# USB0_CTRL register map
Vendor: Texas Instruments
Peripheral module from a debugger description file (folder am335x).
Registers are 32-bit, read-write, no defined reset value unless marked. A register's access mark holds for its fields unless they carry their own. Offsets are as the file gives them; lines under a group give offsets from that group; [hi:lo] are bit positions; {n}, {i} and the like mark numbered series; 'fields as' and 'values as' point back to an identical list; <NAME> marks a mode.

## USB0_CTRL
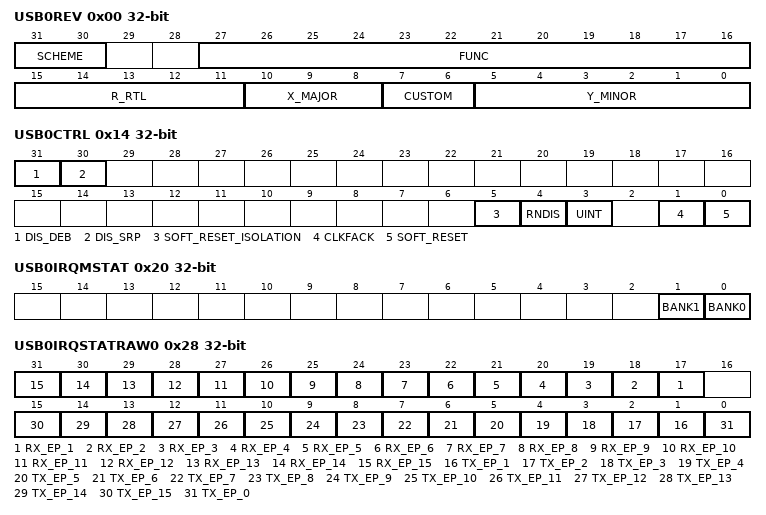
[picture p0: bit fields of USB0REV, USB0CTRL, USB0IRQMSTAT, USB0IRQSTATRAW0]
0x00 USB0REV ro
  [31:30] SCHEME — Used to distinguish between legacy interface scheme and current. 0 = Legacy 1 = Current
  [27:16] FUNC — Function indicates a software compatible module family.
  [15:11] R_RTL — RTL revision. Will vary depending on release.
  [10:8] X_MAJOR — Major revision.
  [7:6] CUSTOM — Custom revision
  [5:0] Y_MINOR — Minor revision. USB0 Revision Register
0x14 USB0CTRL
  [31] DIS_DEB — Disable the VBUS debouncer circuit fix
  [30] DIS_SRP — Disable the OTG Session Request Protocol (SRP) AVALID circuit fix. When enabled (=0) this allows additional time for the VBUS signal to be measured against the VBUS thresholds. The time is specified in the USB0 SRP Fix Time Register.
  [5] SOFT_RESET_ISOLATION — Soft reset isolation. When high this bit forces all USB0 signals that connect to the USBSS to known values during a soft reset via bit 0 of this register. This bit should be set high prior to setting bit 0 and cleared after bit 0 is cleared.
  [4] RNDIS — Global RNDIS mode enable for all endpoints.
  [3] UINT — USB interrupt enable 1 = Legacy 0 = Current (recommended setting); If uint is set high, then the mentor controller generic interrupt for USB[9] will be generated (if enabled). This requires S/W to read the mentor controller's registers to determine which interrupt from USB[0] to USB[7] that occurred.; If uint is set low, then the usb20otg_f module will automatically read the mentor controller's registers and set the appropriate interrupt from USB[0] to USB[7] (if enabled). The generic interrupt for USB[9] will not be generated.
  [1] CLKFACK — Clock stop fast ack enable.
  [0] SOFT_RESET — Software reset of USB0. Write 0 = no action Write 1 = Initiate software reset Read 0 = Reset done, no action Read 1 = Reset ongoing; Both the soft_reset and soft_reset_isolation bits should be asserted simultaneously. This will cause the following sequence of actions to occur over multiple cycles:;; - All USB0 output signals will go to a known constant value via multiplexers. This removes the possibility of timing errors due to the asynchronous resets.; - All USB0 registers will be reset.; - The USB0 resets will be de-asserted.; - The reset isolation multiplexer inputs will be de-selected.; - Both the soft_reset and soft_reset_isolation bits will be automatically cleared.;; Setting only the soft_reset_isolation bit will cause all USB0 output signals to go to a known constant value via multiplexers. This will prevent future access to USB0. To clear this condition the USBSS must be reset via a hard or soft reset.
0x18 USB0STAT ro
  [0] DRVVBUS — Current DRVVBUS value USB0 Status Register
0x20 USB0IRQMSTAT ro
  [1] BANK1 — 0: No events pending from IRQ_STATUS_1 1: At least one event is pending from IRQ_STATUS_1
  [0] BANK0 — 0: No events pending from IRQ_STATUS_0 1: At least one event is pending from IRQ_STATUS_0 USB0 IRQ_MERGED_STATUS Register
0x28 USB0IRQSTATRAW0
  [n+16] RX_EP_{n} (n=1..15) — Interrupt status for RX endpoint {n}
  [n] TX_EP_{n} (n=1..15) — Interrupt status for TX endpoint {n}
  [0] TX_EP_0 — Interrupt status for TX endpoint 0 USB0 IRQ_STATUS_RAW_0 Register
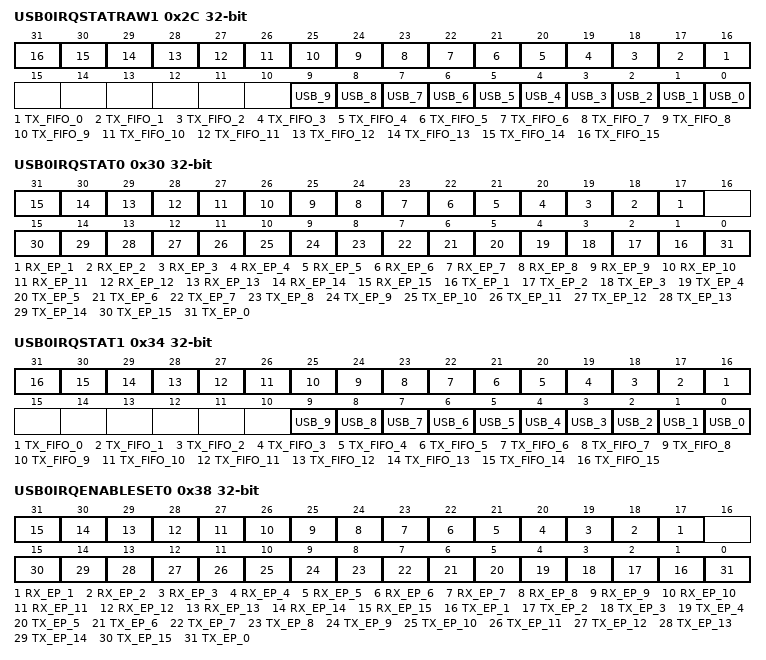
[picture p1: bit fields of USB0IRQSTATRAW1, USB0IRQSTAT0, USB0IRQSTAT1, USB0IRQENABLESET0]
0x2C USB0IRQSTATRAW1
  [n+16] TX_FIFO_{n} (n=0..15) — Interrupt status for TX FIFO endpoint {n}
  [9] USB_9 — Interrupt status for Mentor controller USB_INT generic interrupt
  [8] USB_8 — Interrupt status for DRVVBUS level change
  [7] USB_7 — Interrupt status for VBUS < VBUS valid threshold
  [6] USB_6 — Interrupt status for SRP detected
  [5] USB_5 — Interrupt status for device disconnected (host mode)
  [4] USB_4 — Interrupt status for device connected (host mode)
  [3] USB_3 — Interrupt status for SOF started
  [2] USB_2 — Interrupt status for Reset signaling detected (peripheral mode) Babble detected (host mode)
  [1] USB_1 — Interrupt status for Resume signaling detected
  [0] USB_0 — Interrupt status for Suspend signaling detected USB0 IRQ_STATUS_RAW_1 Register
0x30 USB0IRQSTAT0
  [n+16] RX_EP_{n} (n=1..15) — Interrupt status for RX endpoint {n}
  [n] TX_EP_{n} (n=1..15) — Interrupt status for TX endpoint {n}
  [0] TX_EP_0 — Interrupt status for TX endpoint 0 USB0 IRQ_STATUS_0 Register
0x34 USB0IRQSTAT1
  [n+16] TX_FIFO_{n} (n=0..15) — Interrupt status for TX FIFO endpoint {n}
  [9] USB_9 — Interrupt status for Mentor controller USB_INT generic interrupt
  [8] USB_8 — Interrupt status for DRVVBUS level change
  [7] USB_7 — Interrupt status for VBUS < VBUS valid threshold
  [6] USB_6 — Interrupt status for SRP detected
  [5] USB_5 — Interrupt status for device disconnected (host mode)
  [4] USB_4 — Interrupt status for device connected (host mode)
  [3] USB_3 — Interrupt status for SOF started
  [2] USB_2 — Interrupt status for Reset signaling detected (peripheral mode) Babble detected (host mode)
  [1] USB_1 — Interrupt status for Resume signaling detected
  [0] USB_0 — Interrupt status for Suspend signaling detected USB0 IRQ_STATUS_1 Register
0x38 USB0IRQENABLESET0
  [n+16] RX_EP_{n} (n=1..15) — Interrupt enable for RX endpoint {n}
  [n] TX_EP_{n} (n=1..15) — Interrupt enable for TX endpoint {n}
  [0] TX_EP_0 — Interrupt enable for TX endpoint 0 USB0 IRQ_ENABLE_SET_0 Register
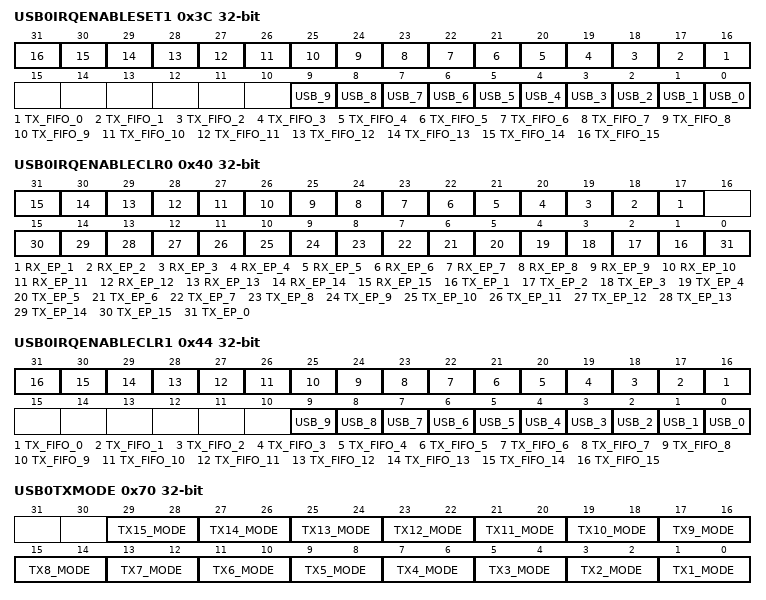
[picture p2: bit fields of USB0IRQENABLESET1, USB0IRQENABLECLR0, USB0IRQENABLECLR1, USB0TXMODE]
0x3C USB0IRQENABLESET1
  [n+16] TX_FIFO_{n} (n=0..15) — Interrupt enable for TX FIFO endpoint {n}
  [9] USB_9 — Interrupt enable for Mentor controller USB_INT generic interrupt
  [8] USB_8 — Interrupt enable for DRVVBUS level change
  [7] USB_7 — Interrupt enable for VBUS < VBUS valid threshold
  [6] USB_6 — Interrupt enable for SRP detected
  [5] USB_5 — Interrupt enable for device disconnected (host mode)
  [4] USB_4 — Interrupt enable for device connected (host mode)
  [3] USB_3 — Interrupt enable for SOF started
  [2] USB_2 — Interrupt enable for Reset signaling detected (peripheral mode) Babble detected (host mode)
  [1] USB_1 — Interrupt enable for Resume signaling detected
  [0] USB_0 — Interrupt enable for Suspend signaling detected USB0 IRQ_ENABLE_SET_1 Register
0x40 USB0IRQENABLECLR0
  [n+16] RX_EP_{n} (n=1..15) — Interrupt enable for RX endpoint {n}
  [n] TX_EP_{n} (n=1..15) — Interrupt enable for TX endpoint {n}
  [0] TX_EP_0 — Interrupt enable for TX endpoint 0 USB0 IRQ_ENABLE_CLR_0 Register
0x44 USB0IRQENABLECLR1
  [n+16] TX_FIFO_{n} (n=0..15) — Interrupt enable for TX FIFO endpoint {n}
  [9] USB_9 — Interrupt enable for Mentor controller USB_INT generic interrupt
  [8] USB_8 — Interrupt enable for DRVVBUS level change
  [7] USB_7 — Interrupt enable for VBUS < VBUS valid threshold
  [6] USB_6 — Interrupt enable for SRP detected
  [5] USB_5 — Interrupt enable for device disconnected (host mode)
  [4] USB_4 — Interrupt enable for device connected (host mode)
  [3] USB_3 — Interrupt enable for SOF started
  [2] USB_2 — Interrupt enable for Reset signaling detected (peripheral mode) Babble detected (host mode)
  [1] USB_1 — Interrupt enable for Resume signaling detected
  [0] USB_0 — Interrupt enable for Suspend signaling detected USB0 IRQ_ENABLE_CLR_1 Register
0x70 USB0TXMODE
  [2n-1:2n-2] TX{n}_MODE (n=2..15) — 00: Transparent Mode on TX endpoint {n-1} 01: RNDIS Mode on TX endpoint {n-1} 10: CDC Mode on TX endpoint {n-1} 11: Generic RNDIS Mode on TX endpoint {n-1}
  [1:0] TX1_MODE — 00: Transparent Mode on TX endpoint 0 01: RNDIS Mode on TX endpoint 0 10: CDC Mode on TX endpoint 0 11: Generic RNDIS Mode on TX endpoint 0 USB0 Tx Mode Registers
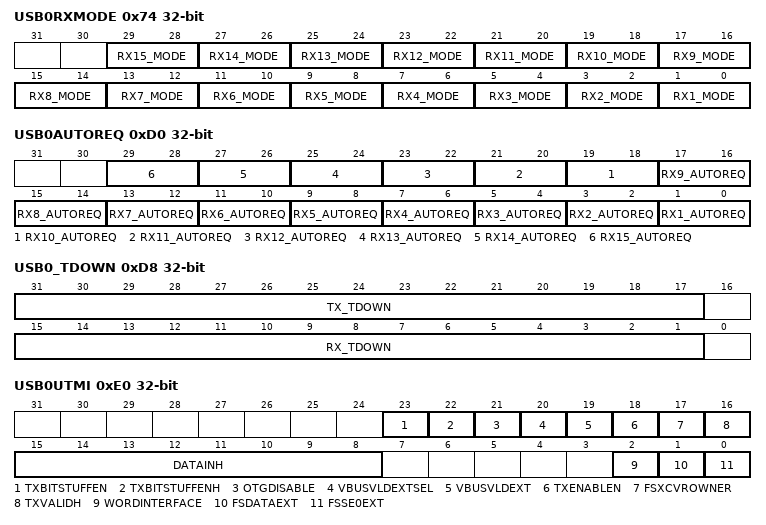
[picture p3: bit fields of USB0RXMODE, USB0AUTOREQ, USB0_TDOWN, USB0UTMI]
0x74 USB0RXMODE
  [2n-1:2n-2] RX{n}_MODE (n=10..15) — 00: Transparent Mode on RX endpoint {n-1} 01: RNDIS Mode on RX endpoint {n-1} 10: CDC Mode on RX endpoint {n-1} 11: Generic RNDIS or Infinite Mode on RX endpoint {n-1}
  [17:16] RX9_MODE — 00: Transparent Mode on RX endpoint 8 01: RNDIS Mode on RX endpoint 8 10: CDC Mode on RX endpoint 8 11: Generic RNDIS Mode on RX endpoint 8
  [2n-1:2n-2] RX{n}_MODE (n=2..8) — 00: Transparent Mode on RX endpoint {n-1} 01: RNDIS Mode on RX endpoint {n-1} 10: CDC Mode on RX endpoint {n-1} 11: Generic RNDIS or Infinite Mode on RX endpoint {n-1}
  [1:0] RX1_MODE — 00: Transparent Mode on RX endpoint 0 01: RNDIS Mode on RX endpoint 0 10: CDC Mode on RX endpoint 0 11: Generic RNDIS or Infinite Mode on RX endpoint 0 Each RX endpoint can be configured into 1 of 5 packet termination modes. Transparent mode (b00) * Supports USB endpoint sizes of o FS : 8, 16, 32, 64, and 1023 o HS : 64, 128, 512, and 1024 * Mentor Controller's RXMAXP/TXMAXP must be a valid USB endpoint size. * With autoreq=3 XDMA will always generate a ReqPkt's at the end of the packet. * With autoreq=1 XDMA will never generatate a ReqPkt at the end of the packet. * Each USB packet is equivalent to a single CPPI DMA packet. * Each received CPPI packet will be no larger than the USB max packet size (1023 bytes for FS, 1024 bytes for HS) and will be both a SOP and EOP. * Transmitted CPPI packets can be no larger than the USB max packet size. * Primarily used for interrupt or isochronous endpoints, as CPU will receive an interrupt for every USB packet (if enabled). RNDIS mode (b01) * Supports USB endpoint sizes of o FS : 64 o HS : 64, 128, 512, and 1024 * Mentor controller's RXMAXP/TXMAXP must be an integer multiple of the USB endpoint size. * With autoreq=3 XDMA will always generate a ReqPkt's at the end of the packet. * With autoreq=1 XDMA will continue the generation of ReqPkt's to the Mentor controller until a short packet is received. * Supports transmission of CPPI packets larger than the USB max packet size. * The end of a CPPI packet is defined by a USB short packet (a USB packet less than the USB max packet size). * In the case where the CPPI packet is an exact multiple of the USB max packet size, a zero length terminating packet is used (XDMA recognizes this terminating packet on reception, and generates it on transmission). * Designed for use in an RNDIS compliant networking type of USB device and bulk endpoints Linux CDC mode (b10) * Same as RNDIS mode, except terminating packet has 1-byte of 0 data. * Designed for use with a Linux OS and USB driver stack and bulk endpoints. Generic RNDIS mode (b11 and Generic RNDIS EP N Size register is greater than 0) * Same as RNDIS mode, except the end of a CPPI packet is determined by a USB short packet or when the value in the GENERIC RNDIS EPn SIZE Register is reached (Rx mode only)(i.e. Tx mode does not use this register). The CPU configures this register with a value that is a multiple of the corresponding endpoint size. * No terminating packet is used. * Designed for general bulk endpoint use where specific packet terminations are not required. * Transmit mode transfers only support FS or HS EP sizes through the XDMA and Mentor controller. The CPPI DMA size can be of any legal size as defined by the CPPI 4.1 specification. Infinite mode (b11 and Generic RNDIS EP N Size register equal to 0) * Same as RNDIS mode, except the end of a CPPI packet is determined by a USB short packet or when the CPPI DMA closes up the packet after a defined number of buffers have been filled. This is defined in Rx Channel N Global Configuration Register bits 28:26 rx_max_buffer_cnt. * The CPPI DMA will ignore SOPs generated by the XDMA. * The XDMA packet is assumed to be infinite. * The XDMA starts the packet with a SOP (ignored by the CPPI DMA). * The XDMA ends the packet when a short packet occurs. * Short packets are defined when RXMAXP (0x14) is not equal to RXCOUNT (0x18). RXMAXP and RXCOUNT are both registers within the Mentor controller. * The XDMA will continue to request RX packets from the Mentor controller until a short packet is received. * When the CPPI is configured for chaining mode, the Buffer Descriptor sizes must be integer multiples of the RXMAXP size. * Transmit mode is not supported. * USB0 or USB1 Auto Req register should be set to AUTO REQ ALWAYS.
{0x7C+4i} USB0GENRNDISEP{i} (i=1..15)
  [16:0] EP{i}_SIZE — Generic RNDIS packet size. USB0 Generic RNDIS EP N Size Register
0xD0 USB0AUTOREQ
  [2n-1:2n-2] RX{n}_AUTOREQ (n=2..15) — RX endpoint {n-1} Auto Req enable 00 = no auto req 01 = auto req on all but EOP 10 = reserved 11 = auto req always
  [1:0] RX1_AUTOREQ — RX endpoint 0 Auto Req enable 00 = no auto req 01 = auto req on all but EOP 10 = reserved 11 = auto req always USB0 Auto Req Registers
0xD4 USB0SRPFIXTIME
  [31:0] SRPFIXTIME — SRP Fix maximum time in 60 MHz cycles. Default is 700 ms. USB0 SRP Fix Time Register
0xD8 USB0_TDOWN
  [31:17] TX_TDOWN — Tx Endpoint Teardown. Write '1' to corresponding bit to set. Read as '0'. Bit 31 = Endpoint 15 ... Bit 17 = Endpoint 1
  [15:1] RX_TDOWN — RX Endpoint Teardown. Write '1' to corresponding bit to set. Read as '0'. Bit 15 = Endpoint 15 ... Bit 1 = Endpoint 1
0xE0 USB0UTMI
  [23] TXBITSTUFFEN — PHY UTMI input for signal txbitstuffen
  [22] TXBITSTUFFENH — PHY UTMI input for signal txbitstuffenh
  [21] OTGDISABLE — PHY UTMI input for signal otgdisable
  [20] VBUSVLDEXTSEL — PHY UTMI input for signal vbusvldextsel
  [19] VBUSVLDEXT — PHY UTMI input for signal vbusvldext
  [18] TXENABLEN — PHY UTMI input for signal txenablen
  [17] FSXCVROWNER — PHY UTMI input for signal fsxcvrowner
  [16] TXVALIDH — PHY UTMI input for signal txvalidh
  [15:8] DATAINH — PHY UTMI input for signal datainh
  [2] WORDINTERFACE — PHY UTMI input for signal wordinterface
  [1] FSDATAEXT — PHY UTMI input for signal fsdataext
  [0] FSSE0EXT — PHY UTMI input for signal fsse0ext USB0 PHY UTMI Register
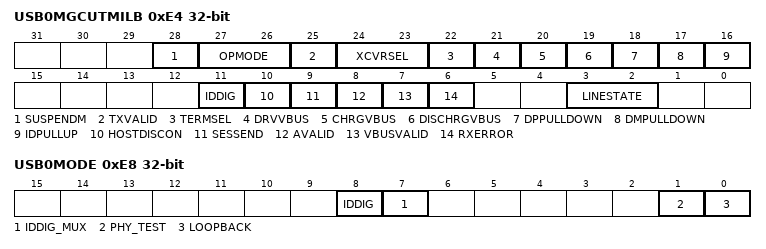
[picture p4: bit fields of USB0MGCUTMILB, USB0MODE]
0xE4 USB0MGCUTMILB access per field
  [28] SUSPENDM ro — loopback test observed value for suspendm
  [27:26] OPMODE ro — loopback test observed value for opmode
  [25] TXVALID ro — loopback test observed value for txvalid
  [24:23] XCVRSEL ro — loopback test observed value for xcvrsel
  [22] TERMSEL ro — loopback test observed value for termsel
  [21] DRVVBUS ro — loopback test observed value for drvvbus
  [20] CHRGVBUS ro — loopback test observed value for chrgvbus
  [19] DISCHRGVBUS ro — loopback test observed value for dischrgvbus
  [18] DPPULLDOWN ro — loopback test observed value for dppulldown
  [17] DMPULLDOWN ro — loopback test observed value for dmpulldown
  [16] IDPULLUP ro — loopback test observed value for idpullup
  [11] IDDIG rw — loopback test value for iddig
  [10] HOSTDISCON rw — loopback test value for hostdiscon
  [9] SESSEND rw — loopback test value for sessend
  [8] AVALID rw — loopback test value for avalid
  [7] VBUSVALID rw — loopback test value for vbusvalid
  [6] RXERROR rw — loopback test value for rxerror
  [3:2] LINESTATE rw — loopback test value for linestate
0xE8 USB0MODE
  [8] IDDIG — MGC input value for iddig 0=A type 1=B type
  [7] IDDIG_MUX — Multiplexer control for IDDIG signal going to the controller. 0 = IDDIG is from PHY0. 1 = IDDIG is from bit 8 (IDDIG) of this USB0MODE register.
  [1] PHY_TEST — PHY test 0 = Normal mode 1 = PHY test mode
  [0] LOOPBACK — Loopback test mode 0 = Normal mode 1 = Loopback test mode USB0 Mode Register
